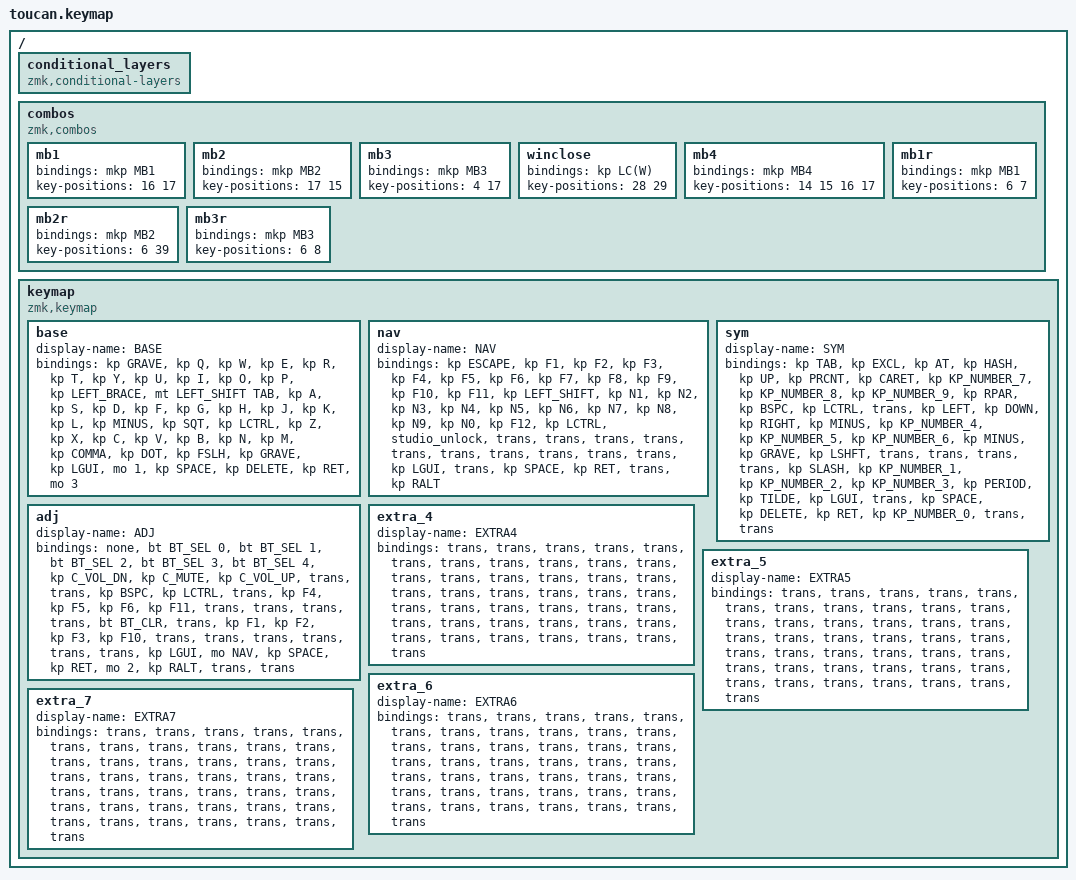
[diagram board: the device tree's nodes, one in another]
#include <behaviors.dtsi>
#include <dt-bindings/zmk/bt.h>
#include <dt-bindings/zmk/keys.h>
#include <dt-bindings/zmk/pointing.h>

#define BASE 0
#define NAV 1
#define SYM 2
#define ADJ 3
#define EXTRA4 4
#define EXTRA5 5
#define EXTRA6 6
#define EXTRA7 7

/ {
    // Conditional Layersの設定を無効化
    conditional_layers {
        compatible = "zmk,conditional-layers";
    };

    combos {
        compatible = "zmk,combos";

        mb1 {
            bindings = <&mkp MB1>;
            key-positions = <16 17>;
        };

        mb2 {
            bindings = <&mkp MB2>;
            key-positions = <17 15>;
        };

        mb3 {
            bindings = <&mkp MB3>;
            key-positions = <4 17>;
        };

        winclose {
            bindings = <&kp LC(W)>;
            key-positions = <28 29>;
        };

        mb4 {
            bindings = <&mkp MB4>;
            key-positions = <14 15 16 17>;
        };

        mb1r {
            bindings = <&mkp MB1>;
            key-positions = <6 7>;
        };

        mb2r {
            bindings = <&mkp MB2>;
            key-positions = <6 39>;
        };

        mb3r {
            bindings = <&mkp MB3>;
            key-positions = <6 8>;
        };
    };

    keymap {
        compatible = "zmk,keymap";

        base {
            display-name = "BASE";
            bindings = <
&kp GRAVE  &kp Q  &kp W  &kp E  &kp R  &kp T  &kp Y  &kp U  &kp I  &kp O  &kp P  &kp LEFT_BRACE  &mt LEFT_SHIFT TAB  &kp A  &kp S  &kp D  &kp F  &kp G  &kp H  &kp J  &kp K  &kp L  &kp MINUS  &kp SQT  &kp LCTRL  &kp Z  &kp X  &kp C  &kp V  &kp B  &kp N  &kp M  &kp COMMA  &kp DOT  &kp FSLH  &kp GRAVE  &kp LGUI  &mo 1  &kp SPACE  &kp DELETE  &kp RET  &mo 3
            >;
        };

        nav {
            display-name = "NAV";
            bindings = <
&kp ESCAPE  &kp F1  &kp F2  &kp F3  &kp F4  &kp F5  &kp F6  &kp F7  &kp F8  &kp F9  &kp F10  &kp F11  &kp LEFT_SHIFT  &kp N1  &kp N2  &kp N3  &kp N4  &kp N5  &kp N6  &kp N7  &kp N8  &kp N9  &kp N0  &kp F12  &kp LCTRL  &studio_unlock  &trans  &trans  &trans  &trans  &trans  &trans  &trans  &trans  &trans  &trans  &kp LGUI  &trans  &kp SPACE  &kp RET  &trans  &kp RALT
            >;
        };

        sym {
            display-name = "SYM";
            bindings = <
&kp TAB  &kp EXCL  &kp AT  &kp HASH  &kp UP  &kp PRCNT  &kp CARET  &kp KP_NUMBER_7  &kp KP_NUMBER_8  &kp KP_NUMBER_9  &kp RPAR  &kp BSPC  &kp LCTRL  &trans  &kp LEFT  &kp DOWN  &kp RIGHT  &kp MINUS  &kp KP_NUMBER_4  &kp KP_NUMBER_5  &kp KP_NUMBER_6  &kp MINUS  &kp GRAVE  &kp LSHFT  &trans  &trans  &trans  &trans  &kp SLASH  &kp KP_NUMBER_1  &kp KP_NUMBER_2  &kp KP_NUMBER_3  &kp PERIOD  &kp TILDE  &kp LGUI  &trans  &kp SPACE  &kp DELETE  &kp RET  &kp KP_NUMBER_0  &trans  &trans
            >;
        };

        adj {
            display-name = "ADJ";
            bindings = <
&none  &bt BT_SEL 0  &bt BT_SEL 1  &bt BT_SEL 2  &bt BT_SEL 3  &bt BT_SEL 4  &kp C_VOL_DN  &kp C_MUTE  &kp C_VOL_UP  &trans  &trans  &kp BSPC  &kp LCTRL  &trans  &kp F4  &kp F5  &kp F6  &kp F11  &trans  &trans  &trans  &trans  &bt BT_CLR  &trans  &kp F1  &kp F2  &kp F3  &kp F10  &trans  &trans  &trans  &trans  &trans  &trans  &kp LGUI  &mo NAV  &kp SPACE  &kp RET  &mo 2  &kp RALT  &trans  &trans
            >;
        };

        extra_4 {
            display-name = "EXTRA4";
            bindings = <
&trans  &trans  &trans  &trans  &trans  &trans  &trans  &trans  &trans  &trans  &trans  &trans  &trans  &trans  &trans  &trans  &trans  &trans  &trans  &trans  &trans  &trans  &trans  &trans  &trans  &trans  &trans  &trans  &trans  &trans  &trans  &trans  &trans  &trans  &trans  &trans  &trans  &trans  &trans  &trans  &trans  &trans
            >;
        };

        extra_5 {
            display-name = "EXTRA5";
            bindings = <
&trans  &trans  &trans  &trans  &trans  &trans  &trans  &trans  &trans  &trans  &trans  &trans  &trans  &trans  &trans  &trans  &trans  &trans  &trans  &trans  &trans  &trans  &trans  &trans  &trans  &trans  &trans  &trans  &trans  &trans  &trans  &trans  &trans  &trans  &trans  &trans  &trans  &trans  &trans  &trans  &trans  &trans
            >;
        };

        extra_6 {
            display-name = "EXTRA6";
            bindings = <
&trans  &trans  &trans  &trans  &trans  &trans  &trans  &trans  &trans  &trans  &trans  &trans  &trans  &trans  &trans  &trans  &trans  &trans  &trans  &trans  &trans  &trans  &trans  &trans  &trans  &trans  &trans  &trans  &trans  &trans  &trans  &trans  &trans  &trans  &trans  &trans  &trans  &trans  &trans  &trans  &trans  &trans
            >;
        };

        extra_7 {
            display-name = "EXTRA7";
            bindings = <
&trans  &trans  &trans  &trans  &trans  &trans  &trans  &trans  &trans  &trans  &trans  &trans  &trans  &trans  &trans  &trans  &trans  &trans  &trans  &trans  &trans  &trans  &trans  &trans  &trans  &trans  &trans  &trans  &trans  &trans  &trans  &trans  &trans  &trans  &trans  &trans  &trans  &trans  &trans  &trans  &trans  &trans
            >;
        };
    };
};
